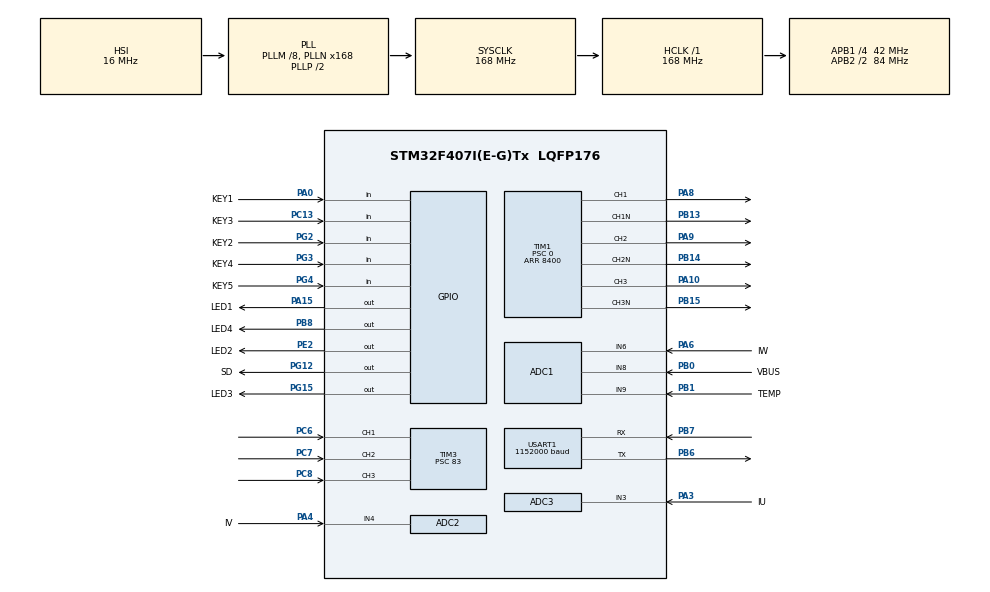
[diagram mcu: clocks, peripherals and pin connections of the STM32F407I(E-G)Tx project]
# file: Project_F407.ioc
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ADC1.Channel-3\#ChannelRegularConversion=ADC_CHANNEL_8
ADC1.Channel-4\#ChannelInjectedConversion=ADC_CHANNEL_6
ADC1.Channel-5\#ChannelRegularConversion=ADC_CHANNEL_9
ADC1.ContinuousConvMode=ENABLE
ADC1.DMAContinuousRequests=ENABLE
ADC1.ExternalTrigInjecConv=ADC_EXTERNALTRIGINJECCONV_T1_CC4
ADC1.ExternalTrigInjecConvEdge=ADC_EXTERNALTRIGINJECCONVEDGE_FALLING
ADC1.InjNumberOfConversion=1
ADC1.InjectedOffset-4\#ChannelInjectedConversion=0
ADC1.InjectedRank-4\#ChannelInjectedConversion=1
ADC1.Mode=ADC_TRIPLEMODE_INJECSIMULT
ADC1.NbrOfConversion=2
ADC1.NbrOfConversionFlag=1
ADC1.Rank-3\#ChannelRegularConversion=1
ADC1.Rank-5\#ChannelRegularConversion=2
ADC1.SamplingTime-3\#ChannelRegularConversion=ADC_SAMPLETIME_84CYCLES
ADC1.SamplingTime-4\#ChannelInjectedConversion=ADC_SAMPLETIME_3CYCLES
ADC1.SamplingTime-5\#ChannelRegularConversion=ADC_SAMPLETIME_84CYCLES
ADC1.ScanConvMode=ENABLE
ADC1.master=1
ADC2.Channel-1\#ChannelRegularConversion=ADC_CHANNEL_4
ADC2.Channel-2\#ChannelInjectedConversion=ADC_CHANNEL_4
ADC2.InjNumberOfConversion=1
ADC2.InjectedOffset-2\#ChannelInjectedConversion=0
ADC2.InjectedRank-2\#ChannelInjectedConversion=1
ADC2.Mode=ADC_TRIPLEMODE_INJECSIMULT
ADC2.NbrOfConversionFlag=1
ADC2.Rank-1\#ChannelRegularConversion=1
ADC2.SamplingTime-1\#ChannelRegularConversion=ADC_SAMPLETIME_3CYCLES
ADC2.SamplingTime-2\#ChannelInjectedConversion=ADC_SAMPLETIME_3CYCLES
ADC2.ScanConvMode=ENABLE
ADC3.Channel-6\#ChannelRegularConversion=ADC_CHANNEL_3
ADC3.Channel-7\#ChannelInjectedConversion=ADC_CHANNEL_3
ADC3.ContinuousConvMode=ENABLE
ADC3.InjNumberOfConversion=1
ADC3.InjectedConvMode=AutoInjected
ADC3.InjectedOffset-7\#ChannelInjectedConversion=0
ADC3.InjectedRank-7\#ChannelInjectedConversion=1
ADC3.Mode=ADC_TRIPLEMODE_INJECSIMULT
ADC3.NbrOfConversion=1
ADC3.NbrOfConversionFlag=1
ADC3.Rank-6\#ChannelRegularConversion=1
ADC3.SamplingTime-6\#ChannelRegularConversion=ADC_SAMPLETIME_3CYCLES
ADC3.SamplingTime-7\#ChannelInjectedConversion=ADC_SAMPLETIME_3CYCLES
ADC3.ScanConvMode=ENABLE
Dma.ADC1.2.Direction=DMA_PERIPH_TO_MEMORY
Dma.ADC1.2.FIFOMode=DMA_FIFOMODE_DISABLE
Dma.ADC1.2.Instance=DMA2_Stream0
Dma.ADC1.2.MemDataAlignment=DMA_MDATAALIGN_HALFWORD
Dma.ADC1.2.MemInc=DMA_MINC_ENABLE
Dma.ADC1.2.Mode=DMA_CIRCULAR
Dma.ADC1.2.PeriphDataAlignment=DMA_PDATAALIGN_HALFWORD
Dma.ADC1.2.PeriphInc=DMA_PINC_DISABLE
Dma.ADC1.2.Priority=DMA_PRIORITY_LOW
Dma.Request0=USART1_RX
Dma.Request1=USART1_TX
Dma.Request2=ADC1
Dma.USART1_RX.0.Direction=DMA_PERIPH_TO_MEMORY
Dma.USART1_RX.0.FIFOMode=DMA_FIFOMODE_DISABLE
Dma.USART1_RX.0.Instance=DMA2_Stream2
Dma.USART1_RX.0.MemDataAlignment=DMA_MDATAALIGN_BYTE
Dma.USART1_RX.0.MemInc=DMA_MINC_ENABLE
Dma.USART1_RX.0.Mode=DMA_NORMAL
Dma.USART1_RX.0.PeriphDataAlignment=DMA_PDATAALIGN_BYTE
Dma.USART1_RX.0.PeriphInc=DMA_PINC_DISABLE
Dma.USART1_RX.0.Priority=DMA_PRIORITY_LOW
Dma.USART1_TX.1.Direction=DMA_MEMORY_TO_PERIPH
Dma.USART1_TX.1.FIFOMode=DMA_FIFOMODE_DISABLE
Dma.USART1_TX.1.Instance=DMA2_Stream7
Dma.USART1_TX.1.MemDataAlignment=DMA_MDATAALIGN_BYTE
Dma.USART1_TX.1.MemInc=DMA_MINC_ENABLE
Dma.USART1_TX.1.Mode=DMA_NORMAL
Dma.USART1_TX.1.PeriphDataAlignment=DMA_PDATAALIGN_BYTE
Dma.USART1_TX.1.PeriphInc=DMA_PINC_DISABLE
Dma.USART1_TX.1.Priority=DMA_PRIORITY_LOW
Mcu.Family=STM32F4
Mcu.Name=STM32F407I(E-G)Tx
Mcu.Package=LQFP176
NVIC.ADC_IRQn=true\:2\:0\:true\:false\:true\:true\:true\:true
NVIC.DMA2_Stream0_IRQn=true\:0\:0\:false\:false\:true\:false\:true\:true
NVIC.DMA2_Stream2_IRQn=true\:3\:0\:true\:false\:true\:false\:true\:true
NVIC.DMA2_Stream7_IRQn=true\:3\:0\:true\:false\:true\:false\:true\:true
NVIC.PriorityGroup=NVIC_PRIORITYGROUP_4
NVIC.TIM1_UP_TIM10_IRQn=true\:5\:0\:true\:false\:true\:true\:true\:true
NVIC.TIM3_IRQn=true\:3\:0\:true\:false\:true\:true\:true\:true
NVIC.TIM7_IRQn=true\:5\:0\:true\:false\:true\:true\:true\:true
NVIC.USART1_IRQn=true\:5\:0\:true\:false\:true\:true\:true\:true
PA0-WKUP.GPIO_Label=KEY1
PA0-WKUP.Signal=GPIO_Input
PA10.Signal=S_TIM1_CH3
PA13.Mode=Serial_Wire
PA13.Signal=SYS_JTMS-SWDIO
PA14.Mode=Serial_Wire
PA14.Signal=SYS_JTCK-SWCLK
PA15.GPIO_Label=LED1
PA15.GPIO_PuPd=GPIO_PULLUP
PA15.PinState=GPIO_PIN_SET
PA15.Signal=GPIO_Output
PA3.GPIO_Label=IU
PA3.Signal=ADCx_IN3
PA4.GPIO_Label=IV
PA4.Signal=ADCx_IN4
PA6.GPIO_Label=IW
PA6.Signal=ADCx_IN6
PA8.Signal=S_TIM1_CH1
PA9.Signal=S_TIM1_CH2
PB0.GPIO_Label=VBUS
PB0.Signal=ADCx_IN8
PB1.GPIO_Label=TEMP
PB1.Signal=ADCx_IN9
PB13.Mode=PWM Generation1 CH1 CH1N
PB13.Signal=TIM1_CH1N
PB14.Mode=PWM Generation2 CH2 CH2N
PB14.Signal=TIM1_CH2N
PB15.Mode=PWM Generation3 CH3 CH3N
PB15.Signal=TIM1_CH3N
PB6.Mode=Asynchronous
PB6.Signal=USART1_TX
PB7.Mode=Asynchronous
PB7.Signal=USART1_RX
PB8.GPIO_Label=LED4
PB8.GPIO_PuPd=GPIO_PULLUP
PB8.PinState=GPIO_PIN_SET
PB8.Signal=GPIO_Output
PC13-ANTI_TAMP.GPIO_Label=KEY3
PC13-ANTI_TAMP.Signal=GPIO_Input
PC6.Signal=S_TIM3_CH1
PC7.Signal=S_TIM3_CH2
PC8.Signal=S_TIM3_CH3
PE2.GPIO_Label=LED2
PE2.GPIO_PuPd=GPIO_PULLUP
PE2.PinState=GPIO_PIN_SET
PE2.Signal=GPIO_Output
PG12.GPIO_Label=SD
PG12.Signal=GPIO_Output
PG15.GPIO_Label=LED3
PG15.GPIO_PuPd=GPIO_PULLUP
PG15.PinState=GPIO_PIN_SET
PG15.Signal=GPIO_Output
PG2.GPIO_Label=KEY2
PG2.Signal=GPIO_Input
PG3.GPIO_Label=KEY4
PG3.Signal=GPIO_Input
PG4.GPIO_Label=KEY5
PG4.Signal=GPIO_Input
PH0-OSC_IN.Mode=HSE-External-Oscillator
PH0-OSC_IN.Signal=RCC_OSC_IN
PH1-OSC_OUT.Mode=HSE-External-Oscillator
PH1-OSC_OUT.Signal=RCC_OSC_OUT
ProjectManager.HeapSize=0x200
ProjectManager.StackSize=0x400
ProjectManager.TargetToolchain=MDK-ARM V5.32
RCC.48MHZClocksFreq_Value=84000000
RCC.AHBFreq_Value=168000000
RCC.APB1CLKDivider=RCC_HCLK_DIV4
RCC.APB1Freq_Value=42000000
RCC.APB1TimFreq_Value=84000000
RCC.APB2CLKDivider=RCC_HCLK_DIV2
RCC.APB2Freq_Value=84000000
RCC.APB2TimFreq_Value=168000000
RCC.CortexFreq_Value=168000000
RCC.HCLKFreq_Value=168000000
RCC.HSE_VALUE=25000000
RCC.HSI_VALUE=16000000
RCC.LSE_VALUE=32768
RCC.PLLM=8
RCC.PLLN=168
RCC.SYSCLKFreq_VALUE=168000000
RCC.SYSCLKSource=RCC_SYSCLKSOURCE_PLLCLK
RCC.VCOOutputFreq_Value=336000000
SH.ADCx_IN3.0=ADC3_IN3,IN3
SH.ADCx_IN4.0=ADC2_IN4,IN4
SH.ADCx_IN6.0=ADC1_IN6,IN6
SH.ADCx_IN8.0=ADC1_IN8,IN8
SH.ADCx_IN9.0=ADC1_IN9,IN9
SH.S_TIM1_CH1.0=TIM1_CH1,PWM Generation1 CH1 CH1N
SH.S_TIM1_CH2.0=TIM1_CH2,PWM Generation2 CH2 CH2N
SH.S_TIM1_CH3.0=TIM1_CH3,PWM Generation3 CH3 CH3N
SH.S_TIM3_CH1.0=TIM3_CH1,Xored_Inputs_Hall_Sensor_Interface
SH.S_TIM3_CH2.0=TIM3_CH2,Xored_Inputs_Hall_Sensor_Interface
SH.S_TIM3_CH3.0=TIM3_CH3,Xored_Inputs_Hall_Sensor_Interface
TIM1.AutomaticOutput=TIM_AUTOMATICOUTPUT_DISABLE
TIM1.Channel-PWM\ Generation1\ CH1\ CH1N=TIM_CHANNEL_1
TIM1.Channel-PWM\ Generation2\ CH2\ CH2N=TIM_CHANNEL_2
TIM1.Channel-PWM\ Generation3\ CH3\ CH3N=TIM_CHANNEL_3
TIM1.Channel-PWM\ Generation4\ No\ Output=TIM_CHANNEL_4
TIM1.CounterMode=TIM_COUNTERMODE_CENTERALIGNED1
TIM1.DeadTime=20
TIM1.OffStateIDLEMode=TIM_OSSI_DISABLE
TIM1.OffStateRunMode=TIM_OSSR_DISABLE
TIM1.Period=8400
TIM1.Prescaler=0
TIM1.Pulse-PWM\ Generation4\ No\ Output=8390
TIM3.Prescaler=83
TIM7.Period=999
TIM7.Prescaler=83
USART1.BaudRate=1152000
USART1.VirtualMode=VM_ASYNC
VP_CRC_VS_CRC.Mode=CRC_Activate
VP_TIM1_VS_ClockSourceINT.Mode=Internal
VP_TIM1_VS_no_output4.Mode=PWM Generation4 No Output
VP_TIM7_VS_ClockSourceINT.Mode=Enable_Timer
board=custom

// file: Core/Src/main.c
/* USER CODE BEGIN Header */
/**
  ******************************************************************************
  * @file           : main.c
  * @brief          : Main program body
  ******************************************************************************
  * @attention
  *
  * Copyright (c) 2025 STMicroelectronics.
  * All rights reserved.
  *
  * This software is licensed under terms that can be found in the LICENSE file
  * in the root directory of this software component.
  * If no LICENSE file comes with this software, it is provided AS-IS.
  *
  ******************************************************************************
  */
/* USER CODE END Header */
#include "main.h"
#include "adc.h"
#include "crc.h"
#include "dma.h"
#include "tim.h"
#include "usart.h"
#include "gpio.h"

/* USER CODE BEGIN Includes */
#include "w_adc.h"
#include "foc.h"
#include "hall.h"

/* USER CODE END Includes */

/* USER CODE BEGIN PTD */
const char SoftWareID[] = "T006";

/* USER CODE END PTD */

void SystemClock_Config(void);

int main(void)
{

  /* MCU Configuration--------------------------------------------------------*/

  /* Reset of all peripherals, Initializes the Flash interface and the Systick. */
  HAL_Init();

  /* Configure the system clock */
  SystemClock_Config();

  /* Initialize all configured peripherals */
  MX_GPIO_Init();
  MX_DMA_Init();
  MX_USART1_UART_Init();
  MX_CRC_Init();
  MX_TIM7_Init();
  MX_TIM3_Init();
  MX_ADC3_Init();
  MX_ADC1_Init();
  MX_ADC2_Init();
  MX_TIM1_Init();
  /* USER CODE BEGIN 2 */
  HAL_TIM_Base_Start_IT(&htim7);
  Hall_Enable();
  ADC_Enable();
  BLDC_Enable();
  BLDC_PidInit();
  /* USER CODE END 2 */

  /* Infinite loop */
  /* USER CODE BEGIN WHILE */
  while (1)
  {
    TaskSchedule();
    /* USER CODE END WHILE */

  }
}

void SystemClock_Config(void)
{
  RCC_OscInitTypeDef RCC_OscInitStruct = {0};
  RCC_ClkInitTypeDef RCC_ClkInitStruct = {0};

  /** Configure the main internal regulator output voltage
  */
  __HAL_RCC_PWR_CLK_ENABLE();
  __HAL_PWR_VOLTAGESCALING_CONFIG(PWR_REGULATOR_VOLTAGE_SCALE1);

  /** Initializes the RCC Oscillators according to the specified parameters
  * in the RCC_OscInitTypeDef structure.
  */
  RCC_OscInitStruct.OscillatorType = RCC_OSCILLATORTYPE_HSI;
  RCC_OscInitStruct.HSIState = RCC_HSI_ON;
  RCC_OscInitStruct.HSICalibrationValue = RCC_HSICALIBRATION_DEFAULT;
  RCC_OscInitStruct.PLL.PLLState = RCC_PLL_ON;
  RCC_OscInitStruct.PLL.PLLSource = RCC_PLLSOURCE_HSI;
  RCC_OscInitStruct.PLL.PLLM = 8;
  RCC_OscInitStruct.PLL.PLLN = 168;
  RCC_OscInitStruct.PLL.PLLP = RCC_PLLP_DIV2;
  RCC_OscInitStruct.PLL.PLLQ = 4;
  if (HAL_RCC_OscConfig(&RCC_OscInitStruct) != HAL_OK)
  {
    Error_Handler();
  }

  /** Initializes the CPU, AHB and APB buses clocks
  */
  RCC_ClkInitStruct.ClockType = RCC_CLOCKTYPE_HCLK|RCC_CLOCKTYPE_SYSCLK
                              |RCC_CLOCKTYPE_PCLK1|RCC_CLOCKTYPE_PCLK2;
  RCC_ClkInitStruct.SYSCLKSource = RCC_SYSCLKSOURCE_PLLCLK;
  RCC_ClkInitStruct.AHBCLKDivider = RCC_SYSCLK_DIV1;
  RCC_ClkInitStruct.APB1CLKDivider = RCC_HCLK_DIV4;
  RCC_ClkInitStruct.APB2CLKDivider = RCC_HCLK_DIV2;

  if (HAL_RCC_ClockConfig(&RCC_ClkInitStruct, FLASH_LATENCY_5) != HAL_OK)
  {
    Error_Handler();
  }
}

void Error_Handler(void)
{
  __disable_irq();
  while (1)
  {
  }
}
